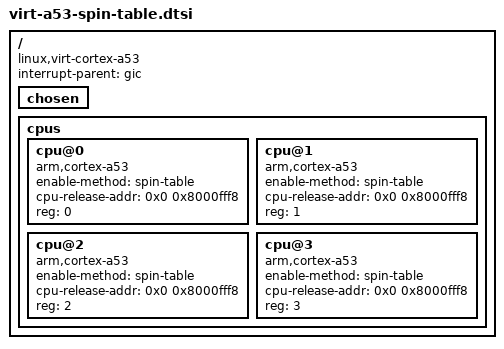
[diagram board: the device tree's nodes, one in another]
/dts-v1/;
/* spin-table cpu-release-addr 内存空间 */
/memreserve/ 0x80000000 0x00010000;

/ {
	compatible = "linux,virt-cortex-a53";
	interrupt-parent = <&gic>;
	#size-cells = <2>;
	#address-cells = <2>;


	chosen {};

	cpus {
		#size-cells = <0>;
		#address-cells = <1>;

		cpu@0 {
			device_type = "cpu";
			compatible = "arm,cortex-a53";
			enable-method = "spin-table";
                        cpu-release-addr = <0x0 0x8000fff8>;
			reg = <0>;
		};

		cpu@1 {
			device_type = "cpu";
			compatible = "arm,cortex-a53";
			enable-method = "spin-table";
                        cpu-release-addr = <0x0 0x8000fff8>;
			reg = <1>;
		};

		cpu@2 {
			device_type = "cpu";
			compatible = "arm,cortex-a53";
			enable-method = "spin-table";
                        cpu-release-addr = <0x0 0x8000fff8>;
			reg = <2>;
		};

		cpu@3 {
			device_type = "cpu";
			compatible = "arm,cortex-a53";
			enable-method = "spin-table";
                        cpu-release-addr = <0x0 0x8000fff8>;
			reg = <3>;
		};
	};
};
